# CY8C4247AZS_M485 register map
File version: 0.1
PSoC 4200M
Registers are 32-bit, read-write, no defined reset value unless marked. A register's access mark holds for its fields unless they carry their own. Offsets are from the block's base; lines under a group give offsets from that group; [hi:lo] are bit positions; {n}, {i} and the like mark numbered series; 'fields as' and 'values as' point back to an identical list; <NAME> marks a mode.

## Memory map
0x00000000 I2C_Master — Serial Communication Block
0x00000000 Phase_Counter
0x00000000 HB25_PWM
0x00000000 EZI2C_Slave — Serial Communication Block
0x00000000 ADC_Infrared — Sequencing SAR ADC
0x00000000 UARTCOMMS — Serial Communication Block
0x00000000 HCSR04_Timer
0x40000000 DMAC — DMAC Registers
0x400F0072 HCSR04_Control

## Phase_Counter
Base 0x00000000
0x400F0000 Phase_Counter_COUNTER — UDB.A0 - Current Counter Value
0x400F0020 Phase_Counter_PERIOD — UDB.D0 - Assigned Period
0x400F0030 Phase_Counter_COMPARE — UDB.D1 - Assigned Compare Value
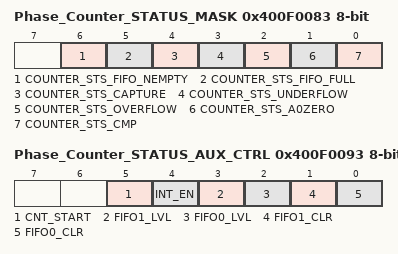
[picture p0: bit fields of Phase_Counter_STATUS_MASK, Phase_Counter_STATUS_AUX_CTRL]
0x400F0083 Phase_Counter_STATUS_MASK 8-bit — UDB Status bits Interrupt Mask Enable Register
  [6] COUNTER_STS_FIFO_NEMPTY — FIFO Not Empty Status
  [5] COUNTER_STS_FIFO_FULL — FIFO Full Status
  [4] COUNTER_STS_CAPTURE — Capture Status
  [3] COUNTER_STS_UNDERFLOW — Underflow status
  [2] COUNTER_STS_OVERFLOW — Overflow status
  [1] COUNTER_STS_A0ZERO — A0 Zero ouput status
  [0] COUNTER_STS_CMP — Compare output status
0x400F0093 Phase_Counter_STATUS_AUX_CTRL 8-bit — UDB Auxilliary Control Register
  [5] CNT_START — FIFO0 clear
    0=E_CNT_START0 (Disable counter); 1=E_CNT_START1 (Enable counter)
  [4] INT_EN
    0=E_INT_EN0 (Interrupt disabled); 1=E_INT_EN1 (Interrupt enabled)
  [3] FIFO1_LVL — FIFO level
    0=E_FIFO_LVL_0 (FIFO LVL: input mode: FIFO not full; output mode: FIFO not empty); 1=E_FIFO_LVL_1 (FIFO LVL: input mode: FIFO at least 1/2 empty; output mode: FIFO at least 1/2 full)
  [2] FIFO0_LVL — FIFO level
    values as FIFO1_LVL
  [1] FIFO1_CLR — FIFO1 clear
    0=E_FIFO_CLR_0 (Normal FIFO operation); 1=E_FIFO_CLR_1 (Clear FIFO state)
  [0] FIFO0_CLR — FIFO0 clear
    values as FIFO1_CLR

## HB25_PWM
Base 0x00000000
0x40200148 COUNTER — Current counter value
0x4020014C CC — Compare / capture value
0x40200150 CC_BUF — Compare / capture buffer value
0x40200154 PERIOD — Period value
0x40200158 PERIOD_BUF — Period buffer value

## HCSR04_Timer
Base 0x00000000
0x40200108 COUNTER — Current counter value
0x4020010C CC — Compare / capture value
0x40200110 CC_BUF — Compare / capture buffer value
0x40200114 PERIOD — Period value
0x40200118 PERIOD_BUF — Period buffer value

## HCSR04_Control
Base 0x400F0072
0x00 HCSR04_Control_CONTROL_REG 8-bit
